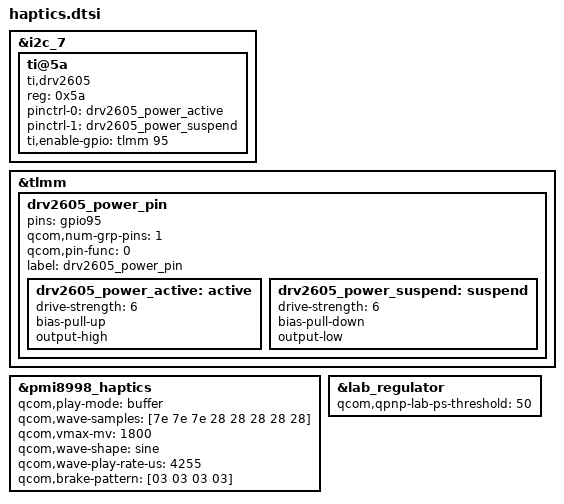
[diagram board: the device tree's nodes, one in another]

&i2c_7 {
        status = "okay";
        ti@5a{
                compatible = "ti,drv2605";
                reg = <0x5a>;
                pinctrl-names = "active","suspend";
                pinctrl-0 = <&drv2605_power_active>;
                pinctrl-1 = <&drv2605_power_suspend>;
                ti,enable-gpio=<&tlmm 95 0x0>;
        };
};
&tlmm {
        drv2605_power_pin{
                pins = "gpio95";
                qcom,num-grp-pins = <1>;
                qcom,pin-func = <0>;
                label = "drv2605_power_pin";
                drv2605_power_active: active {
                        drive-strength = <6>;
                        bias-pull-up;
                        output-high;
                };
                drv2605_power_suspend: suspend {
                        drive-strength = <6>;
                        bias-pull-down;
                        output-low;
                };
        };
};

&pmi8998_haptics {
		qcom,play-mode = "buffer";
		qcom,wave-samples = [7e 7e 7e 28 28 28 28 28];
		qcom,vmax-mv = <1800>;
		qcom,wave-shape = "sine";
		qcom,wave-play-rate-us = <4255>;
		qcom,brake-pattern = [03 03 03 03];
};

&lab_regulator {
    qcom,qpnp-lab-ps-threshold = <50>;
};
